# RL6955_IP_SVD register map
Vendor: Realtek
Registers are 32-bit, read-write, reset 0x0 unless marked. A register's access mark holds for its fields unless they carry their own. Offsets are from the block's base; [hi:lo] are bit positions; <NAME> marks a mode.

## PAGE5_OFF
Base 0x40000000
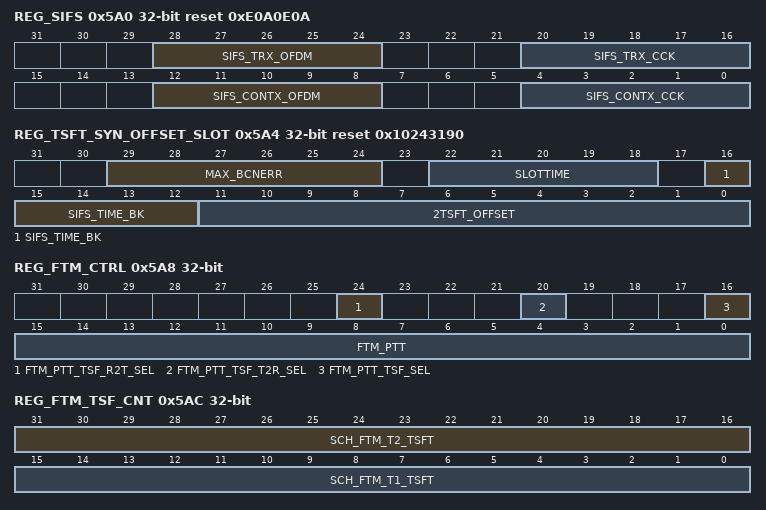
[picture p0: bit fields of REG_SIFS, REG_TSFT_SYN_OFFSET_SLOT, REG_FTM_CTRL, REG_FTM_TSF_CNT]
0x5A0 REG_SIFS reset 0xE0A0E0A
  [28:24] SIFS_TRX_OFDM — This register sets the SIFS time required in NAV protection period after receiving any immediate response. for example Ack-Data or RTS/CTS-Data. It is in unit of us.
  [20:16] SIFS_TRX_CCK — This register sets the SIFS time required in NAV protection period after receiving any immediate response. for example Ack-Data or RTS/CTS-Data. It is in unit of us.
  [12:8] SIFS_CONTX_OFDM — This register sets the SIFS time required for consecutive TX events for example CTS2S-Data, or broadcast bursting. It is in unit of us.
  [4:0] SIFS_CONTX_CCK — This register sets the SIFS time required for consecutive TX events for example CTS2S-Data, or broadcast bursting. It is in unit of us.
0x5A4 REG_TSFT_SYN_OFFSET_SLOT reset 0x10243190
  [29:24] MAX_BCNERR — When beacon TX error counter goes over this threshold, Beacon will transmit within PIFS. Unit is 4
  [22:18] SLOTTIME — This register sets the slot time value mentioned in 802.11 specification. It is in units of us. Default: 0x9
  [16:12] SIFS_TIME_BK — Hw will break aggr. In sifs condition
  [11:0] 2TSFT_OFFSET — tsft sync. Offset (bcn0 sync to bcn1 offset or bcn1 sync to bcn0 offset). Unit : 128us, default is 50ms
0x5A8 REG_FTM_CTRL
  [24] FTM_PTT_TSF_R2T_SEL — 0:R2T latch count sync tsf of port 0 1: R2T latch count sync tsf of port 1
  [20] FTM_PTT_TSF_T2R_SEL — 0:T2R latch count sync tsf of port 0 1: T2R latch count sync tsf of port 1
  [16] FTM_PTT_TSF_SEL — 0: sync tsf of port 0 1: sync tsf of port 1
  [15:0] FTM_PTT — partial tsf timer setting
0x5AC REG_FTM_TSF_CNT ro
  [31:16] SCH_FTM_T2_TSFT — R2T latch count sync tsf timer
  [15:0] SCH_FTM_T1_TSFT — T2R latch count sync tsf timer
0x5B0 REG_P0_TSFTR_L reset 0x1
  [31:0] P0_TSF_TIMER_L — low 32bits of port0's tsft
0x5B4 REG_P0_TSFTR_H
  [31:0] P0_TSF_TIMER_H — high 32bits of port0's tsft
0x5B8 REG_FREERUN_CNT_L reset 0x1
  [31:0] FREERUN_CNT_TIMER_L — LOW 32bits of freerun cnt
0x5BC REG_FREERUN_CNT_H
  [31:0] FREERUN_CNT_TIMER_H — high 32bits of freerun cnt
0x5C0 REG_P2_TSFTR_L reset 0x1
  [31:0] P2_TSF_TIMER_L — low 32bits of port2's tsft (NAN)
0x5C4 REG_P2_TSFTR_H
  [31:0] P2_TSF_TIMER_H — high 32bits of port2's tsft (NAN)
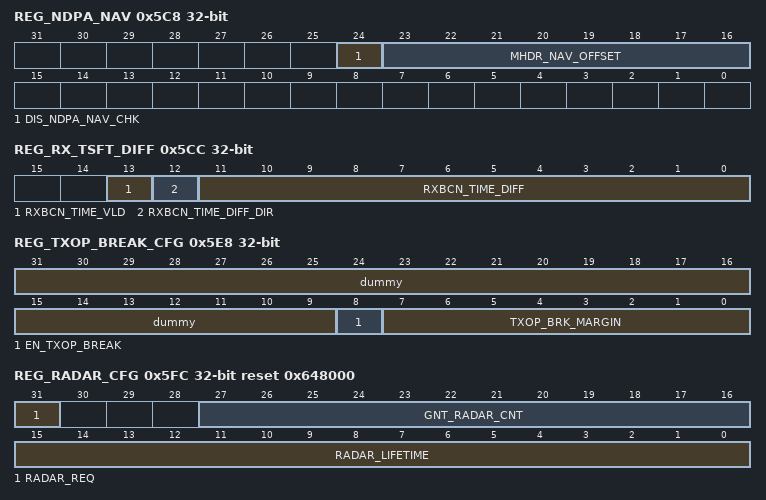
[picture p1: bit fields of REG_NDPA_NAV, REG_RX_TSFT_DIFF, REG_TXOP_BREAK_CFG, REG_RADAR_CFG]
0x5C8 REG_NDPA_NAV
  [24] DIS_NDPA_NAV_CHK — 1-->tx NDPA/NDP can cross TBTT,0-->tx NDPA/NDP can't cross TBTT
  [23:16] MHDR_NAV_OFFSET — NDPA NAV compensation value
0x5CC REG_RX_TSFT_DIFF ro
  [13] RXBCN_TIME_VLD — 1: indicate [12:0] is valid. Write 1 to clear this bit
  [12] RXBCN_TIME_DIFF_DIR — 1: wmac_rx_tsf > TSFT 0: wmac_rx_tsf <= TSFT
  [11:0] RXBCN_TIME_DIFF — unit:32us wmac_rx_tsf - TSFT. [12] is the sign bit
0x5D0 REG_TM_TSFT_T1_T3 ro
  [23:0] SCH_TM_TSFT_T1_T3 — T1: Latch tsft timer of Tx TM frame, unit: 1us T3: Latch tsft timer of Tx ACK frame, unit: 1us
0x5D4 REG_TM_TSFT_T2_T4 ro
  [23:0] SCH_TM_TSFT_T2_T4 — T2: Latch tsft timer of Rx TM frame, unit: 1us T4: Latch tsft timer of Rx ACK frame, unit: 1us
0x5D8 REG_TSFT_HIOE_RFON_L ro
  [31:0] TSFT_AT_HIOE_RFON_L — when hioe_int_chn_on asserted, latch the tsft[31:0] (select port by 0x1520[0])
0x5DC REG_TSFT_HIOE_RFON_H ro
  [31:0] TSFT_AT_HIOE_RFON_H — when hioe_int_chn_on asserted, latch the tsft[63:32] (select port by 0x1520[0])
0x5E0 REG_TSFT_BCN_CCAUP_L ro
  [31:0] TSFT_AT_BCN_CCA_UP_L — when CCA asserted, latch the tsft[31:0] (select port by 0x1520[0]). updated to this register after judging that it is a beacon frame
0x5E4 REG_TSFT_BCN_CCAUP_H ro
  [31:0] TSFT_AT_BCN_CCA_UP_H — when CCA asserted, latch the tsft[63:32] (select port by 0x1520[0]). updated to this register after judging that it is a beacon frame
0x5E8 REG_TXOP_BREAK_CFG
  [31:9] dummy
  [8] EN_TXOP_BREAK — 1: enable TXOP break gen_cmd and TXOP abort TX
  [7:0] TXOP_BRK_MARGIN — extra transtime during TXOP, unit: 2us if data_transtime + BIT_TXOP_BRK_MARGIN*2 exceed the remaining TXOP count, will abort this TX
0x5EC REG_P2_TSFT_BACKUP_L ro reset 0x1
  [31:0] P2_TSF_BACKUP_L — low 32bits of port2's tsft_backup (NAN)
0x5F0 REG_P2_TSFT_BACKUP_H ro
  [31:0] P2_TSF_BACKUP_H — high 32bits of port2's tsft_backup (NAN)
0x5F4 REG_SCHEDULER_DBG ro
  [31:0] DBG_SCHEDULER
0x5F8 REG_SCH_TXCMD ro
  [31:0] SCH_TXCMD — Scheduler TXCMD Content
0x5FC REG_RADAR_CFG reset 0x648000
  [31] RADAR_REQ — asserted when need to tx radar pkt,FW set, SW clear
  [27:16] GNT_RADAR_CNT — Need to wait some time when detect the posedge or negedge of gnt_radar, unit:us
  [15:0] RADAR_LIFETIME — Radar packet lifetime, unit:32us
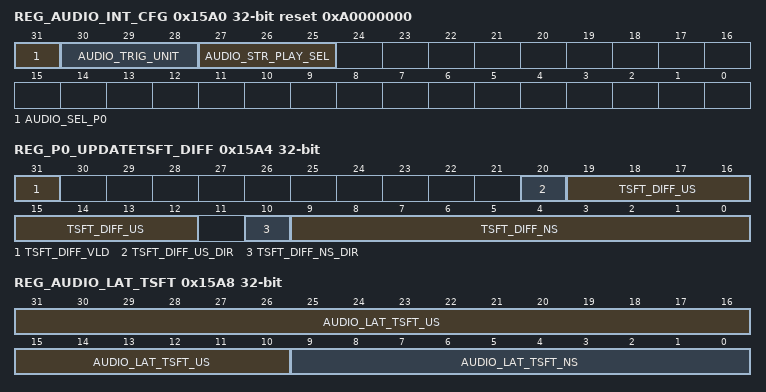
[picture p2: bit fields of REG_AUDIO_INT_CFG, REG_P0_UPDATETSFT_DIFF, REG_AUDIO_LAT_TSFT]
0x15A0 REG_AUDIO_INT_CFG reset 0xA0000000
  [31] AUDIO_SEL_P0 — 1: select P0's TSFT to trigger audio latch count
  [30:28] AUDIO_TRIG_UNIT — 0: trigger audio latch period is 1ms 1: period is 2ms 2: period is 4ms 3: period is 8ms ...... 6: period is 64ms 7: period is 128ms
  [27:25] AUDIO_STR_PLAY_SEL — select ps_timer interrput for audio start play function 1: select ps_timer_a int 2: select ps_timer_b int 3: select ps_timer_c int 4: select ps_timer_d int 5: select ps_timer_e int else: TIE0
0x15A4 REG_P0_UPDATETSFT_DIFF ro
  [31] TSFT_DIFF_VLD — 1: indicate [20:0] is valid. 0: wmac_rx_tsf <= TSFT
  [20] TSFT_DIFF_US_DIR — 1: update_tsft_us > TSFT_us 0: update_tsft_us <= TSFT_us
  [19:12] TSFT_DIFF_US — unit:1us update_tsft_us - TSFT. [20] is the sign bit if diff >=255, this value would be 8'hff
  [10] TSFT_DIFF_NS_DIR — 1: update_tsft_ns > TSFT_ns 0: update_tsft_ns <= TSFT_ns
  [9:0] TSFT_DIFF_NS — unit:1ns update_tsft_ns - TSFT. [10] is the sign bit
0x15A8 REG_AUDIO_LAT_TSFT ro
  [31:10] AUDIO_LAT_TSFT_US — low 22bits of audio latch tsft_us
  [9:0] AUDIO_LAT_TSFT_NS — audio latch tsft_ns
